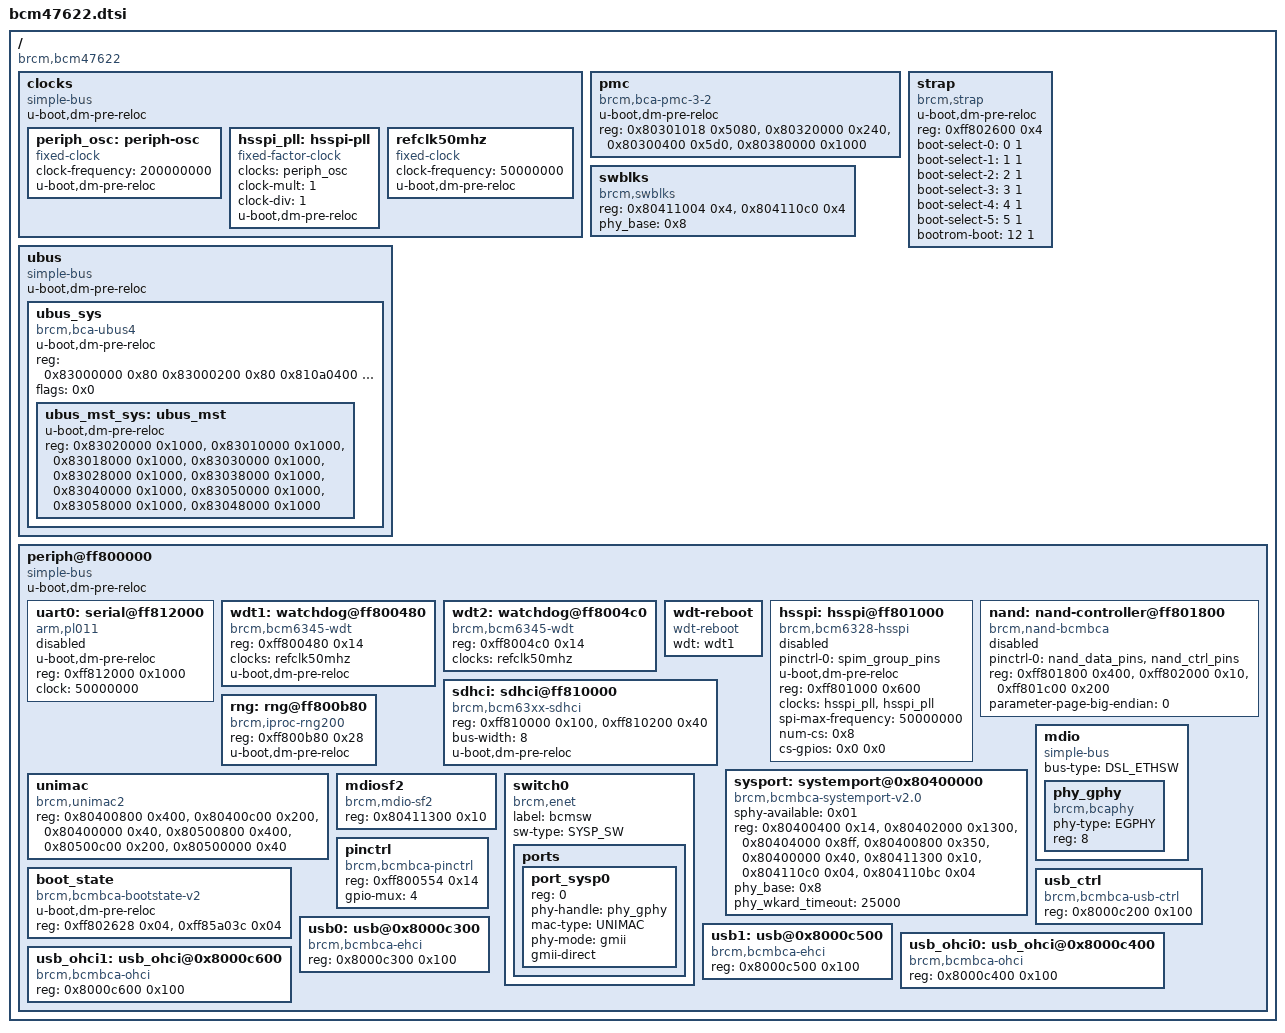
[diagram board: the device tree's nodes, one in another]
// SPDX-License-Identifier: GPL-2.0+
/*
 * Copyright 2019 Broadcom Ltd.
 */

#include "skeleton.dtsi"

/ {
	compatible = "brcm,bcm47622";
	#address-cells = <0x1>;
	#size-cells = <0x1>;

	clocks {
		compatible = "simple-bus";
		#address-cells = <1>;
		#size-cells = <1>;
		ranges;
		u-boot,dm-pre-reloc;

		periph_osc: periph-osc {
			compatible = "fixed-clock";
			#clock-cells = <0>;
			clock-frequency = <200000000>;
			u-boot,dm-pre-reloc;
		};

		hsspi_pll: hsspi-pll {
			compatible = "fixed-factor-clock";
			#clock-cells = <0>;
			clocks = <&periph_osc>;
			clock-mult = <1>;
			clock-div = <1>;
			u-boot,dm-pre-reloc;
		};

		refclk50mhz: refclk50mhz {
			compatible = "fixed-clock";
			#clock-cells = <0>;
			clock-frequency = <50000000>;
			u-boot,dm-pre-reloc;
		};
	};

	pmc {
		u-boot,dm-pre-reloc;
		compatible = "brcm,bca-pmc-3-2";
		reg-names = "pmc", "procmon", "maestro","dtcm"; 
 		reg = <0x80301018 0x5080>,
 		      <0x80320000 0x240>,
 		      <0x80300400 0x5d0>,
 		      <0x80380000 0x1000>;
	};

	strap: strap {
		u-boot,dm-pre-reloc;
		compatible = "brcm,strap";
		reg = <0xff802600 0x4>;
		boot-select-0=<0 1>;
		boot-select-1=<1 1>;
		boot-select-2=<2 1>;
		boot-select-3=<3 1>;
		boot-select-4=<4 1>;
		boot-select-5=<5 1>;
		bootrom-boot=<12 1>;
	};

	swblks {
		compatible = "brcm,swblks";
		reg-names = "xbar-ctrl",
					"sphy-ctrl";

		reg = 	<0x80411004 0x4>,
				<0x804110c0 0x4>;
		phy_base = <0x8>;
	};

	/* UBUS */
	ubus: ubus {
		u-boot,dm-pre-reloc;
		compatible = "simple-bus";
		#address-cells = <1>;
		#size-cells = <1>;
		ranges;

		ubus_sys: ubus_sys {
			u-boot,dm-pre-reloc;
			#address-cells = <1>;
			#size-cells = <1>;
			compatible = "brcm,bca-ubus4";
			reg = <0x83000000 0x80 0x83000200 0x80 0x810a0400 0x400>;
			reg-names = "ubus_systop", "ubus_registration", "ubus_coherency_port";
			flags = <0x0>;

			ubus_mst_sys: ubus_mst {
				u-boot,dm-pre-reloc;
				reg-names = "BIU", "PER", "USB", "PCIE0",
					"PMC", "SYSPORT0", "SYSPORT1", "WIFI0",
					"WIFI1", "SPU";
				reg = <0x83020000 0x1000>,
					<0x83010000 0x1000>,
					<0x83018000 0x1000>,
					<0x83030000 0x1000>,
					<0x83028000 0x1000>,
					<0x83038000 0x1000>,
					<0x83040000 0x1000>,
					<0x83050000 0x1000>,
					<0x83058000 0x1000>,
					<0x83048000 0x1000>;
			};
		};
	};

	periph@ff800000 {
		compatible = "simple-bus";
		#address-cells = <0x1>;
		#size-cells = <0x1>;
		u-boot,dm-pre-reloc;

		uart0: serial@ff812000 {	
			u-boot,dm-pre-reloc;
			compatible = "arm,pl011", "arm,primecell";
			reg = <0xff812000 0x1000>;
			clock = <50000000>;
			status = "disabled";
		};

		wdt1: watchdog@ff800480 {
			compatible = "brcm,bcm6345-wdt";
			reg = <0xff800480 0x14>;
			clocks = <&refclk50mhz>;
			u-boot,dm-pre-reloc;
		};

		wdt2: watchdog@ff8004c0 {
			compatible = "brcm,bcm6345-wdt";
			reg = <0xff8004c0 0x14>;
			clocks = <&refclk50mhz>;
		};

		wdt-reboot {
			compatible = "wdt-reboot";
			wdt = <&wdt1>;
		};

		hsspi: hsspi@ff801000 {
			pinctrl-0 = <&spim_group_pins>;
			pinctrl-names = "default";
			#address-cells = <0x1>;
			#size-cells = <0x0>;
			u-boot,dm-pre-reloc;
			compatible = "brcm,bcm6328-hsspi";
			reg = <0xff801000 0x600>;
			clocks = <&hsspi_pll>, <&hsspi_pll>;
			clock-names = "hsspi", "pll";
			spi-max-frequency = <50000000>;
			num-cs = <0x8>;
			cs-gpios = <0x0 0x0>;
			status = "disabled";
		};

		nand: nand-controller@ff801800 {
			pinctrl-0 = <&nand_data_pins &nand_ctrl_pins>;
			pinctrl-names = "default";	
			compatible = "brcm,nand-bcmbca",
				     "brcm,brcmnand-v7.1",
				     "brcm,brcmnand";
			reg-names = "nand", "nand-int-base", "nand-cache";
			reg = <0xff801800 0x400>,
			      <0xff802000 0x10>,
			      <0xff801c00 0x200>;
			parameter-page-big-endian = <0>;
			status = "disabled";
		};

		sdhci: sdhci@ff810000 {
			compatible = "brcm,bcm63xx-sdhci",
			             "brcm,sdhci-brcmbca";
			reg-names = "sdhci-base", "sdhci-boot";
			reg = <0xff810000 0x100>,
			      <0xff810200 0x40>;	
			bus-width = <8>;
			u-boot,dm-pre-reloc;
		};

		rng: rng@ff800b80 {
			compatible = "brcm,iproc-rng200";
			reg = <0xff800b80 0x28>;
			u-boot,dm-pre-reloc;
		};
		sysport: systemport@0x80400000 {
			compatible = "brcm,bcmbca-systemport-v2.0";
			sphy-available=<0x01>;
			reg-names =
			"systemport-rbuf-base",
			"systemport-rdma-base",
			"systemport-tdma-base",
			"systemport-umac-base",
			"systemport-topctrl-base",
			"systemport-switchmdio-base",
			"sphy-ctrl",
			"phy-test-ctrl";
			reg =   <0x80400400 0x14>,
				<0x80402000 0x1300>,
				<0x80404000 0x8ff>,
				<0x80400800 0x350>,
				<0x80400000 0x40>,
				<0x80411300 0x10>,
				<0x804110c0 0x04>,
				<0x804110bc 0x04>;
			phy_base = <0x8>;
			phy_wkard_timeout = <25000>;
		};

		unimac {
			compatible = "brcm,unimac2";
			reg = <0x80400800 0x400>,
				  <0x80400c00 0x200>,
				  <0x80400000 0x40>,
				  <0x80500800 0x400>,
				  <0x80500c00 0x200>,
				  <0x80500000 0x40>;
		};

		mdio: mdio {
			compatible = "simple-bus";
			bus-type = "DSL_ETHSW";

			#address-cells = <1>;
			#size-cells = <0>;

			phy_gphy:phy_gphy {
				compatible = "brcm,bcaphy";
				phy-type = "EGPHY";
				reg = <8>;
			};
		};

		mdiosf2 {
			compatible = "brcm,mdio-sf2";
			reg = <0x80411300 0x10>;
		};

		switch0:switch0 {
			compatible = "brcm,enet", "brcm,bcmbca-sysp_sw"; 
			label = "bcmsw";
			sw-type = "SYSP_SW";
			
			ports {
				#address-cells = <1>;
				#size-cells = <0>;

				port_sysp0 {
					reg = <0>;
					phy-handle = <&phy_gphy>;
					mac-type = "UNIMAC";
					phy-mode = "gmii";
					gmii-direct;
				};
			};
		};

		boot_state {
			u-boot,dm-pre-reloc;
			compatible = "brcm,bcmbca-bootstate-v2";
			reg-names = "reset_reason", "reset_status";
			reg = <0xff802628 0x04>,
				<0xff85a03c 0x04>;
		};

		pinctrl: pinctrl {
			compatible = "brcm,bcmbca-pinctrl";
			reg = <0xff800554 0x14>;
			gpio-mux = <4>;
		};

		usb_ctrl:usb_ctrl {
			compatible = "brcm,bcmbca-usb-ctrl";
			reg-names = "usb-ctrl";
			reg = <0x8000c200 0x100>;
			status = "okay";
		};

		usb0: usb@0x8000c300 {
			compatible = "brcm,bcmbca-ehci";
			reg-names = "usb-ehci";
			reg = <0x8000c300 0x100>;
		};

		usb1: usb@0x8000c500 {
			compatible = "brcm,bcmbca-ehci";
			reg-names = "usb-ehci";
			reg = <0x8000c500 0x100>;
		};

		usb_ohci0: usb_ohci@0x8000c400 {
			compatible = "brcm,bcmbca-ohci";
			reg-names = "usb-ohci";
			reg = <0x8000c400 0x100>;
		};

		usb_ohci1: usb_ohci@0x8000c600 {
			compatible = "brcm,bcmbca-ohci";
			reg-names = "usb-ohci";
			reg = <0x8000c600 0x100>;
		};
	};
};

#include "bcm47622-pinctrl.dtsi"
